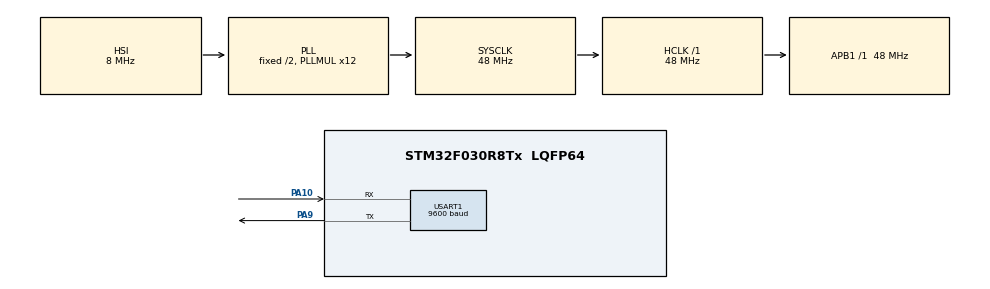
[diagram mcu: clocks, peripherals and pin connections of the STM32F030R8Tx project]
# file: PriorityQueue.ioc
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Mcu.Family=STM32F0
Mcu.Name=STM32F030R8Tx
Mcu.Package=LQFP64
NVIC.USART1_IRQn=true\:0\:0\:false\:false\:true\:true\:true
PA10.Mode=Asynchronous
PA10.Signal=USART1_RX
PA13.Mode=Serial_Wire
PA13.Signal=SYS_SWDIO
PA14.Mode=Serial_Wire
PA14.Signal=SYS_SWCLK
PA9.Mode=Asynchronous
PA9.Signal=USART1_TX
ProjectManager.HeapSize=0x200
ProjectManager.StackSize=0x400
ProjectManager.TargetToolchain=STM32CubeIDE
RCC.AHBFreq_Value=48000000
RCC.APB1Freq_Value=48000000
RCC.APB1TimFreq_Value=48000000
RCC.HCLKFreq_Value=48000000
RCC.PLLMUL=RCC_PLL_MUL12
RCC.SYSCLKFreq_VALUE=48000000
RCC.SYSCLKSource=RCC_SYSCLKSOURCE_PLLCLK
USART1.BaudRate=9600
USART1.VirtualMode-Asynchronous=VM_ASYNC
board=custom

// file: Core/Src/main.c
/* USER CODE BEGIN Header */
/**
  ******************************************************************************
  * @file           : main.c
  * @brief          : Main program body
  ******************************************************************************
  * @attention
  *
  * <h2><center>&copy; Copyright (c) 2022 STMicroelectronics.
  * All rights reserved.</center></h2>
  *
  * This software component is licensed by ST under BSD 3-Clause license,
  * the "License"; You may not use this file except in compliance with the
  * License. You may obtain a copy of the License at:
  *                        opensource.org/licenses/BSD-3-Clause
  *
  ******************************************************************************
  */
/* USER CODE END Header */

#include "main.h"
#include "usart.h"
#include "gpio.h"

/* USER CODE BEGIN Includes */
#include "string.h"
#include "stdlib.h"
#include "stdio.h"
#include "priorityQueue.h"
/* USER CODE END Includes */

/* USER CODE BEGIN PD */
#define MAXQueueSize 5									//Размер очереди
/* USER CODE END PD */

/* USER CODE BEGIN PV */

QueueID_t PriorityQueue;

uint8_t UARTString[20];
uint8_t UARTMsgRXdFlag = 0;

/* USER CODE END PV */

void SystemClock_Config(void);
/* USER CODE BEGIN PFP */
void UARTMessageParser(char *Message);
/* USER CODE END PFP */

int main(void)
{

  /* MCU Configuration--------------------------------------------------------*/

  /* Reset of all peripherals, Initializes the Flash interface and the Systick. */
  HAL_Init();

  /* Configure the system clock */
  SystemClock_Config();

  /* Initialize all configured peripherals */
  MX_GPIO_Init();
  MX_USART1_UART_Init();
  /* USER CODE BEGIN 2 */

  HAL_UART_Receive_IT(&huart1, &UARTString[0],1);

  /* USER CODE END 2 */

  /* Infinite loop */
  while (1)
  {

    /* USER CODE BEGIN 3 */

    if(UARTMsgRXdFlag == 1)
    {
	    UARTMessageParser((char *)UARTString);
	    UARTMsgRXdFlag = 0;
	    memset(&UARTString, 0, sizeof(UARTString));
    }
  }
  /* USER CODE END 3 */
}

void SystemClock_Config(void)
{
  RCC_OscInitTypeDef RCC_OscInitStruct = {0};
  RCC_ClkInitTypeDef RCC_ClkInitStruct = {0};
  RCC_PeriphCLKInitTypeDef PeriphClkInit = {0};

  /** Initializes the CPU, AHB and APB busses clocks
  */
  RCC_OscInitStruct.OscillatorType = RCC_OSCILLATORTYPE_HSI;
  RCC_OscInitStruct.HSIState = RCC_HSI_ON;
  RCC_OscInitStruct.HSICalibrationValue = RCC_HSICALIBRATION_DEFAULT;
  RCC_OscInitStruct.PLL.PLLState = RCC_PLL_ON;
  RCC_OscInitStruct.PLL.PLLSource = RCC_PLLSOURCE_HSI;
  RCC_OscInitStruct.PLL.PLLMUL = RCC_PLL_MUL12;
  RCC_OscInitStruct.PLL.PREDIV = RCC_PREDIV_DIV1;
  if (HAL_RCC_OscConfig(&RCC_OscInitStruct) != HAL_OK)
  {
    Error_Handler();
  }
  /** Initializes the CPU, AHB and APB busses clocks
  */
  RCC_ClkInitStruct.ClockType = RCC_CLOCKTYPE_HCLK|RCC_CLOCKTYPE_SYSCLK
                              |RCC_CLOCKTYPE_PCLK1;
  RCC_ClkInitStruct.SYSCLKSource = RCC_SYSCLKSOURCE_PLLCLK;
  RCC_ClkInitStruct.AHBCLKDivider = RCC_SYSCLK_DIV1;
  RCC_ClkInitStruct.APB1CLKDivider = RCC_HCLK_DIV1;

  if (HAL_RCC_ClockConfig(&RCC_ClkInitStruct, FLASH_LATENCY_1) != HAL_OK)
  {
    Error_Handler();
  }
  PeriphClkInit.PeriphClockSelection = RCC_PERIPHCLK_USART1;
  PeriphClkInit.Usart1ClockSelection = RCC_USART1CLKSOURCE_PCLK1;
  if (HAL_RCCEx_PeriphCLKConfig(&PeriphClkInit) != HAL_OK)
  {
    Error_Handler();
  }
}

/* USER CODE BEGIN 4 */
void UARTMessageParser(char *Message)
{
	uint8_t i = 0;
	uint8_t j = 0;

	QueueItem_t UserItem;
	char UART_TXData[20];

	memset(&UserItem, 0, sizeof(UserItem));

	while(Message[i] != '(')
		i++;

	if (strncmp(&Message[0], "push", (i-1)) == 0)							//вставляем элемент в очередь
	{
		j = ++i;

		while(Message[i] != ',')
			i++;

		strncpy(UserItem.name, &Message[j], (i-j));
		UserItem.priority = atoi(&Message[i+1]);

		QueuePush(&PriorityQueue, UserItem);

		HAL_UART_Transmit(&huart1,(uint8_t*)"OK\r\n", 4, 100);
	}
	else if (strncmp(&Message[0], "pop", (i-1)) == 0)						//достаем первый элемент из очереди
	{
		UserItem = QueuePop(&PriorityQueue);
		HAL_UART_Transmit(&huart1,(uint8_t*)UART_TXData, sprintf(UART_TXData, "%s,%u\r\n",
													UserItem.name, UserItem.priority), 100);
	}
	else if (strncmp(&Message[0], "create", (i-1)) == 0)					//создаем очередь
	{
		QueueCreate(&PriorityQueue, MAXQueueSize);
		HAL_UART_Transmit(&huart1,(uint8_t*)"OK\r\n", 4, 100);
	}
	else if (strncmp(&Message[0], "delete", (i-1)) == 0)					//удаляем очередь
	{
		QueueDelete(&PriorityQueue);
		HAL_UART_Transmit(&huart1,(uint8_t*)"OK\r\n", 4, 100);
	}
	else
		HAL_UART_Transmit(&huart1,(uint8_t*)"Wrong CMD\r\n", 11, 100);

}

void HAL_UART_RxCpltCallback(UART_HandleTypeDef *huart)
{
	static uint8_t n = 0;

	if(huart==&huart1)
	{
		n ++;
		if (UARTString[n-1] == '\n')
		{
			UARTMsgRXdFlag = 1;									//сообщение принято
			n = 0;
		}
		HAL_UART_Receive_IT(&huart1, &UARTString[n],1);
	}
}
/* USER CODE END 4 */

void Error_Handler(void)
{
}

/************************ (C) COPYRIGHT STMicroelectronics *****END OF FILE****/
